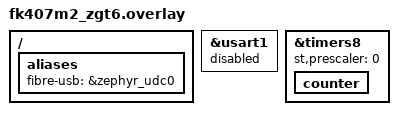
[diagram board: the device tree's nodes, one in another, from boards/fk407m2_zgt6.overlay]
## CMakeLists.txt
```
# SPDX-License-Identifier: Apache-2.0
#
# CASensorSim -- CA (crank angle) sensor signal simulator firmware.
#
# Zephyr app for the FK407M2-ZGT6 (STM32F407ZGT6) bench board. The
# bit-exact cas_core / cas_fault port of the casim golden model lives in
# cas/ (include/ + src/, plain library, host-testable with test/). The app
# layer (src/main.cpp) runs the 100 kHz TIM8 signal path and publishes the
# CasIntf telemetry/parameter interface over Fibre on the native USB bulk
# interface (Type-C connector); the interface autogen code is generated at
# build time from interface/cas_interface.yaml
# with the generator shipped in the Fibre module -- nothing generated is
# committed.
#
# The board is out-of-tree (boards/others/fk407m2_zgt6 in the platform
# workspace), so the workspace root is added to BOARD_ROOT.
#
# Build from the zephyrproject workspace (this repo is registered in
# manifest/west.yml as apps/cas-sim):
#
#   west build -p always -b fk407m2_zgt6 apps/cas-sim
#   west flash -d apps/cas-sim/build

cmake_minimum_required(VERSION 3.20.0)

# Version machinery (odrive_study model, see doc/guideline/version.md): the app
# line derives from this repo's git tags (+ version.txt target), the
# platform line from the workspace repo, checked against
# platform-requires.txt at configure time. The init calls must run before
# find_package(Zephyr) so the generated version.conf reaches kconfig.
include(${CMAKE_CURRENT_LIST_DIR}/../../scripts/git_version.cmake)
git_version_init(${CMAKE_CURRENT_LIST_DIR})
include(${CMAKE_CURRENT_LIST_DIR}/../../scripts/platform_version.cmake)
platform_version_init(${CMAKE_CURRENT_LIST_DIR})

# Platform lib module: provides the boot banner (util/banner), the Fibre
# transport backends (services/fibre-transport) and the rest of the platform
# services -- all of those default to n, so only what prj.conf enables
# (CONFIG_BANNER*, CONFIG_FIBRE_TRANSPORT*) compiles in.
list(APPEND EXTRA_ZEPHYR_MODULES
     ${CMAKE_CURRENT_LIST_DIR}/../../lib)

# Out-of-tree board root (boards/others/fk407m2_zgt6).
list(APPEND BOARD_ROOT ${CMAKE_CURRENT_LIST_DIR}/../..)

find_package(Zephyr REQUIRED HINTS $ENV{ZEPHYR_BASE})
project(cas_sensor_sim LANGUAGES C CXX)

# --------------------------------------------------------------------------
# Virtual CA engine (plain C, shared with the host golden test in test/).
add_subdirectory(cas)

# --------------------------------------------------------------------------
# Fibre interface codegen: interfaces.hpp / endpoints.cpp /
# static_exports.cpp are generated at build time from
# interface/cas_interface.yaml with the interface generator shipped in the
# Fibre module (single source of truth, same three-template invocation the
# upstream module uses).
set(FIBRE_DIR ${ZEPHYR_FIBRE_MODULE_DIR})
if(NOT FIBRE_DIR)
    # Fallback for setups where the module variable is not exported.
    set(FIBRE_DIR ${CMAKE_CURRENT_LIST_DIR}/../../modules/lib/fibre)
endif()
if(NOT EXISTS ${FIBRE_DIR}/tools/interface_generator.py)
    message(FATAL_ERROR "cas-sim: Fibre module not found at ${FIBRE_DIR} "
                        "(run 'west update')")
endif()
message(STATUS "cas-sim: using Fibre module at ${FIBRE_DIR}")

set(AUTOGEN_DIR ${CMAKE_CURRENT_BINARY_DIR}/autogen)
file(MAKE_DIRECTORY ${AUTOGEN_DIR})

# -W ignore::SyntaxWarning: the upstream generator emits harmless
# SyntaxWarnings for its own regex literals on every invocation.
add_custom_command(
  OUTPUT ${AUTOGEN_DIR}/interfaces.hpp
         ${AUTOGEN_DIR}/endpoints.cpp
         ${AUTOGEN_DIR}/static_exports.cpp
  COMMAND ${Python3_EXECUTABLE} -W ignore::SyntaxWarning
          ${FIBRE_DIR}/tools/interface_generator.py
          --definitions ${CMAKE_CURRENT_SOURCE_DIR}/interface/cas_interface.yaml
          --template ${FIBRE_DIR}/cpp/interfaces_template.j2
          --output ${AUTOGEN_DIR}/interfaces.hpp
  COMMAND ${Python3_EXECUTABLE} -W ignore::SyntaxWarning
          ${FIBRE_DIR}/tools/interface_generator.py
          --definitions ${CMAKE_CURRENT_SOURCE_DIR}/interface/cas_interface.yaml
          --template ${FIBRE_DIR}/cpp/legacy_endpoints_template.j2
          --output ${AUTOGEN_DIR}/endpoints.cpp
  COMMAND ${Python3_EXECUTABLE} -W ignore::SyntaxWarning
          ${FIBRE_DIR}/tools/interface_generator.py
          --definitions ${CMAKE_CURRENT_SOURCE_DIR}/interface/cas_interface.yaml
          --template ${FIBRE_DIR}/cpp/static_exports_template.j2
          --output ${AUTOGEN_DIR}/static_exports.cpp
  DEPENDS ${CMAKE_CURRENT_SOURCE_DIR}/interface/cas_interface.yaml
          ${FIBRE_DIR}/tools/interface_generator.py
          ${FIBRE_DIR}/cpp/interfaces_template.j2
          ${FIBRE_DIR}/cpp/legacy_endpoints_template.j2
          ${FIBRE_DIR}/cpp/static_exports_template.j2
  COMMENT "cas-sim: generating fibre autogen from interface YAML"
  VERBATIM
)

target_sources(app PRIVATE
    src/main.cpp
    src/logo.cpp
    ${AUTOGEN_DIR}/endpoints.cpp
    ${AUTOGEN_DIR}/static_exports.cpp
)

target_include_directories(app PRIVATE src ${AUTOGEN_DIR})

# Mirror the Fibre module's own build settings (see modules/lib/fibre/
# CMakeLists.txt): the Fibre headers expect <stdint.h> to be force-included
# and need RTTI (they use typeid/dynamic_cast but never exceptions).
# CONFIG_CPP_RTTI covers the -frtti part for app sources.
target_compile_options(app PRIVATE -include stdint.h)

# fibre-cpp uses ssize_t (channel_discoverer.cpp) without including
# <sys/types.h>; neither picolibc nor newlib provide it through the headers
# those sources include. zephyr_library_compile_options() passes the module's
# own "-include stdint.h" through a generated options_interface_lib_* helper
# target, so that is where the flag has to be redirected: point it at a
# header that also pulls in <sys/types.h> (src/fibre_libc_fix.h). This
# avoids both modifying the west-managed module checkout and appending a
# second "-include" pair, whose duplicate flag would be dropped by CMake's
# transitive option deduplication.
get_target_property(_fibre_libs ..__modules__lib__fibre LINK_LIBRARIES)
foreach(_fibre_lib ${_fibre_libs})
    if(_fibre_lib MATCHES "^options_interface_lib_")
        get_target_property(_fibre_opts ${_fibre_lib} INTERFACE_COMPILE_OPTIONS)
        list(FIND _fibre_opts "stdint.h" _fibre_stdint_idx)
        if(NOT _fibre_stdint_idx EQUAL -1)
            list(REMOVE_AT _fibre_opts ${_fibre_stdint_idx})
            list(INSERT _fibre_opts ${_fibre_stdint_idx}
                 "${CMAKE_CURRENT_LIST_DIR}/src/fibre_libc_fix.h")
            set_target_properties(${_fibre_lib}
                PROPERTIES INTERFACE_COMPILE_OPTIONS "${_fibre_opts}")
        endif()
    endif()
endforeach()
unset(_fibre_libs)
unset(_fibre_lib)
unset(_fibre_opts)
unset(_fibre_stdint_idx)

# Add APP_VERSION_* / PLATFORM_VERSION_* compile definitions once the app
# target exists, and generate the version description headers that firmware
# code includes ("app_version.h" / "platform_version.h").
git_version_finalize()
platform_version_finalize()
version_header_generate(${CMAKE_CURRENT_BINARY_DIR}/generated)
```

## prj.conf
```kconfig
# SPDX-License-Identifier: Apache-2.0
# CASensorSim -- CA sensor signal simulator firmware (FK407M2-ZGT6).
#
# The Fibre protocol (telemetry/parameter interface) runs over the native
# USB bulk interface on the Type-C connector (the board has no USB-UART
# bridge; the transport backend comes from the platform
# lib/services/fibre-transport service, see boards/fk407m2_zgt6.conf).
# USART1 is not used by this app (disabled in the app overlay). Console and
# shell stay disabled: the USB interface carries the protocol stream, and
# the boot banner is visible in the RTT debug build
# (`-DEXTRA_CONF_FILE=rtt.conf`, SEGGER RTT over SWD).

# The USB interface is Fibre's exclusive protocol stream: no console, no
# shell.
CONFIG_CONSOLE=n
CONFIG_SHELL=n
# Explicitly turn off UART_CONSOLE: the board defconfig enables it, but the
# assignment cannot take effect here (CONSOLE=n, no enabled UART instance),
# which makes Kconfig warn on every pristine build.
CONFIG_UART_CONSOLE=n

CONFIG_GPIO=y

# 10 us signal tick on TIM8 (Zephyr counter API); the ISR runs
# double-precision core math, so FP context sharing is required.
CONFIG_COUNTER=y
CONFIG_FPU=y
CONFIG_FPU_SHARING=y

# Fibre (C++ library, west module modules/lib/fibre).
CONFIG_CPP=y
CONFIG_STD_CPP11=y
CONFIG_REQUIRES_FULL_LIBCPP=y
# Fibre uses typeid/dynamic_cast (its module compiles with -frtti).
CONFIG_CPP_RTTI=y
CONFIG_FIBRE=y
# Note: the client role must stay enabled: with FIBRE_ENABLE_CLIENT=0 the
# fibre-cpp headers (legacy_protocol.hpp) do not compile because the Socket
# types they reference are only pulled in via the client headers.
CONFIG_FIBRE_ENABLE_SERVER=1
CONFIG_FIBRE_ENABLE_CLIENT=1
CONFIG_FIBRE_ZEPHYR_EVENT_LOOP=y

# Boot banner (platform module: lib/util/banner) with the CASIM logo. The
# default build has no console backend (the USB interface is Fibre's
# protocol stream), so the page is silently discarded there; it becomes
# visible in the RTT debug build (rtt.conf routes printk into the log
# backend).
CONFIG_BANNER=y
CONFIG_BANNER_LOGO=y
CONFIG_BANNER_PRODUCT="CASensorSim"
CONFIG_BANNER_NAME="CASIM"
```

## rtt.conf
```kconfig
# SPDX-License-Identifier: Apache-2.0
# Optional debug variant: SEGGER RTT logging over SWD (channel 0) while the
# USB bulk interface stays exclusive to the Fibre protocol.
#
#   west build -p always -b fk407m2_zgt6 apps/cas-sim -d apps/cas-sim/build-rtt \
#       -- -DEXTRA_CONF_FILE=rtt.conf
#
# Then expose the RTT channel with OpenOCD:
#   openocd -f interface/stlink.cfg -f target/stm32f4x.cfg \
#       -c "adapter speed 100" -c init -c "reset run" \
#       -c 'rtt setup <addr of _SEGGER_RTT> 0x100 "SEGGER RTT"' \
#       -c "rtt start" -c "rtt server start 9090 0"
#
#   nc 127.0.0.1 9090        # logs (cas-sim + fibre protocol)

CONFIG_LOG=y
CONFIG_USE_SEGGER_RTT=y
CONFIG_LOG_BACKEND_RTT=y
# Route printk (the boot banner page) into the log backend so it reaches
# RTT as well.
CONFIG_LOG_PRINTK=y
```

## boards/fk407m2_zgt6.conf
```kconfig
# SPDX-License-Identifier: Apache-2.0
# CASensorSim on FK407M2-ZGT6: native USB bulk transport for the Fibre
# protocol (Type-C connector; the board has no USB-UART bridge).
#
# The Fibre transport backend lives in the platform lib module
# (lib/services/fibre-transport service), which requires the USB device
# stack. These
# settings mirror the platform board fragment used by the matrix-cards app
# -- cas-sim does not inherit that fragment because it defines its own
# app-level board overlay.

CONFIG_USB_DEVICE_STACK_NEXT=y
CONFIG_FIBRE_TRANSPORT=y
CONFIG_FIBRE_TRANSPORT_USB=y

# USB identity on the host.
CONFIG_FIBRE_TRANSPORT_USB_MANUFACTURER="Xiaofeng"
CONFIG_FIBRE_TRANSPORT_USB_PRODUCT="CASensorSim"

# USB stack stability under the 10 us TIM8 signal-tick load.
CONFIG_UDC_STM32_STACK_SIZE=1024
CONFIG_USBD_THREAD_STACK_SIZE=2048
```

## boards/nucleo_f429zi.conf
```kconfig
# SPDX-License-Identifier: Apache-2.0
# CASensorSim on NUCLEO-F429ZI: Fibre runs over USART3 (the `fibre-uart`
# alias in boards/nucleo_f429zi.overlay) through the platform fibre-transport
# service (mounted in the platform lib module).

CONFIG_FIBRE_TRANSPORT=y
CONFIG_FIBRE_TRANSPORT_UART=y
```

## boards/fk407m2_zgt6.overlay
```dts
/*
 * SPDX-License-Identifier: Apache-2.0
 *
 * CASensorSim app overlay for the FK407M2-ZGT6 (STM32F407ZGT6).
 *
 * The Fibre protocol (CasIntf telemetry/parameter interface) runs over a
 * vendor-specific USB bulk interface on the Type-C connector: the board has
 * no USB-UART bridge, so the native USB device controller is used directly
 * (host side: libusb; the interface carries the Fibre protocol as a raw
 * byte stream). The `fibre-usb` alias below selects the UDC controller for
 * the platform fibre-transport service, which builds the USBD context and
 * the vendor interface (class codes 0xFF/0x01/0x01) on top of it.
 *
 * USART1 is not used by this app and is disabled below, so PA9/PA10 stay
 * free. Console and shell are disabled in prj.conf: the USB interface
 * carries the protocol stream, and the boot banner is visible in the RTT
 * debug build (rtt.conf).
 *
 * Signal generation timing: TIM8 update events at 100 kHz (10 us tick,
 * pin-partition plan); the update interrupt drives cas_step(), the fault
 * injection, the PE0..PE7 output stage and the telemetry mirror (see
 * src/main.cpp).
 */

/ {
	aliases {
		fibre-usb = &zephyr_udc0;
	};
};

&usart1 {
	status = "disabled";
};

&timers8 {
	status = "okay";
	st,prescaler = <0>;

	counter {
		status = "okay";
	};
};
```

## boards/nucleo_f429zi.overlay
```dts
/*
 * SPDX-License-Identifier: Apache-2.0
 *
 * CASensorSim app overlay for the NUCLEO-F429ZI (kept buildable next to
 * the FK407M2-ZGT6 target). USART3 (ST-LINK VCP) carries the Fibre
 * protocol (`fibre-uart` alias); console and shell are disabled in
 * prj.conf. Same signal timing as the fk407m2_zgt6 target: TIM8 update
 * events at 100 kHz driving cas_step() (see src/main.cpp).
 */

/ {
	aliases {
		fibre-uart = &usart3;
	};
};

&timers8 {
	status = "okay";
	st,prescaler = <0>;

	counter {
		status = "okay";
	};
};
```

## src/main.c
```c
/*
 * CASensorSim -- CA (crank angle) sensor signal simulator firmware.
 *
 * Bring-up skeleton for the NUCLEO-F429ZI test-bench board: LED heartbeat
 * to prove the target is alive. The actual product generates 8 digital
 * pickoff channels (TDC1/REF1/A/B/REF2/C/D/TDC2) + 2 SSI absolute-angle
 * streams in real time from a virtual flywheel; the bit-exact core port
 * (cas_core.c / cas_fault.c per HANDOFF.md #7) is the active task and
 * will be driven from a timer here.
 */

#include <errno.h>

#include <zephyr/kernel.h>
#include <zephyr/drivers/gpio.h>

#define BLINK_INTERVAL_MS 500

static const struct gpio_dt_spec led = GPIO_DT_SPEC_GET(DT_ALIAS(led0), gpios);

int main(void)
{
	if (!gpio_is_ready_dt(&led)) {
		printk("CASensorSim: LED device not ready\n");
		return -ENODEV;
	}
	if (gpio_pin_configure_dt(&led, GPIO_OUTPUT_ACTIVE) < 0) {
		printk("CASensorSim: LED configure failed\n");
		return -EIO;
	}

	printk("CASensorSim firmware skeleton (%s)\n", CONFIG_BOARD_TARGET);
	printk("cas_core port pending -- see HANDOFF.md #7\n");

	while (1) {
		gpio_pin_toggle_dt(&led);
		k_msleep(BLINK_INTERVAL_MS);
	}
	return 0;
}
```

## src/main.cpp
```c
/*
 * SPDX-License-Identifier: Apache-2.0
 *
 * CASensorSim -- CA (crank angle) sensor signal simulator firmware.
 *
 * App layer for the FK407M2-ZGT6 (STM32F407ZGT6) bench board. Two
 * concurrent activities:
 *
 *   1. Signal path (100 kHz TIM8 update ISR, 10 us tick per the
 *      pin-partition plan): cas_step() -> cas_fault_apply() -> GPIO
 *      output stage CH00..CH07 = PE0..PE7 (dig[] levels with a single
 *      BSRR write; oe=0 switches the pin to input = high-Z, FR-30) and
 *      the telemetry mirror refresh (below).
 *   2. Fibre protocol over the native USB bulk interface (`fibre-usb`
 *      alias): exposes the CasIntf interface
 *      (interface/cas_interface.yaml) -- readonly telemetry attributes +
 *      set_rpm / set_dig_fault / set_ssi_fault / clear_faults. The Fibre
 *      stack runs in its own event-loop thread; protocol calls never run
 *      in ISR context. The transport backend (fibre_transport::UsbBackend)
 *      comes from the platform lib/services/fibre-transport service.
 *
 * Concurrency model:
 *   - The ISR writes the CasObject telemetry members every tick (plain
 *     32-bit aligned stores; sample_count is 64 bit and may tear when
 *     read -- acceptable for a monotonic counter). The Fibre property
 *     layer reads the members through a pointer at request time, so
 *     host reads always see the latest tick's values.
 *   - Parameter writes (set_rpm / set_*_fault / clear_faults) run on the
 *     event-loop thread and are guarded with irq_lock() so the ISR can
 *     never observe a half-updated profile or fault set.
 *
 * SSI: both absolute-angle words are computed every tick; their pin
 * layer (PA8/PC0 + RS-485 DIR, TIM6 protocol timing) is a later step.
 *
 * Console and shell are disabled (the Fibre transport owns the protocol
 * interface); build with `-DEXTRA_CONF_FILE=rtt.conf` for logs over SEGGER
 * RTT (SWD). The host-side counterpart is host/cas_fibre_test.py.
 */

#include <cmath>

#include <zephyr/kernel.h>
#include <zephyr/drivers/counter.h>
#include <zephyr/drivers/gpio.h>
#include <zephyr/irq.h>
#include <zephyr/logging/log.h>

#include <fibre/fibre.hpp>
#include <fibre/zephyr_event_loop.hpp>

#include "app_version.h"
#include "banner.h"

#include <usb_backend.hpp>
#include "interfaces.hpp"

#include "cas_core.h"
#include "cas_fault.h"
#include "cas_preset.h"

LOG_MODULE_REGISTER(cas_sim);

namespace {

/* --------------------------------------------------------------------------
 * Signal path constants
 */

/* Signal tick: 10 us update events (pin-partition plan, TIM8). */
constexpr uint32_t CAS_TICK_HZ = 100000u;

/* CH00..CH07 sit on PE0..PE7. */
constexpr uint32_t CAS_DIG_MASK = 0xFFu;

/* Firmware version reported over Fibre, encoded (major<<16)|(minor<<8)|patch.
 * Derived at build time from this repo's git state (the generated
 * app_version.h; see CMakeLists.txt) instead of a hardcoded constant: it
 * follows the vX.Y.Z tag / version.txt target of the CASensorSim repo. */
constexpr uint32_t CASIM_FW_VERSION =
    (static_cast<uint32_t>(APP_VERSION_MAJOR) << 16) |
    (static_cast<uint32_t>(APP_VERSION_MINOR) << 8) |
    static_cast<uint32_t>(APP_VERSION_PATCH);

/* --------------------------------------------------------------------------
 * Engine + output stage state (ISR context)
 */

cas_state_t cas_st;
cas_fault_t cas_faults;

/* oe[] bits currently driven as outputs (mode change only on toggle). */
gpio_port_pins_t oe_driven;

const struct gpio_dt_spec led = GPIO_DT_SPEC_GET(DT_ALIAS(led0), gpios);
const struct device *const dig_port = DEVICE_DT_GET(DT_NODELABEL(gpioe));
const struct device *const tick_cnt =
	DEVICE_DT_GET(DT_CHILD(DT_NODELABEL(timers8), counter));

/* --------------------------------------------------------------------------
 * Published Fibre object
 *
 * Member naming is dictated by the generated CasIntfWrapper: every YAML
 * attribute maps to a member `<name>_` (read live through a pointer when
 * the host reads the property), every function to a method.
 */
class CasObject {
public:
    /* -- telemetry (written by the signal ISR every tick) -- */
    uint32_t firmware_version_ = CASIM_FW_VERSION;
    uint32_t tick_hz_ = CAS_TICK_HZ;
    float rpm_ = 0.0f;
    float theta_deg_ = 0.0f;
    uint8_t dig_mask_ = 0;
    uint8_t oe_mask_ = 0;
    int32_t ssi1_ = 0;
    int32_t ssi2_ = 0;
    uint64_t sample_count_ = 0;

    /* -- parameters (event-loop thread, irq_lock() against the ISR) --
     *
     * The legacy Fibre protocol only carries fixed-size int/uint function
     * payloads: enable/pfb/hold/fail flags are uint8 (0/1), the return
     * value is uint8 (1 = accepted, 0 = rejected) and set_rpm takes the
     * speed in milli-rpm (60000 = 60.000 rpm, negative = reverse). */

    uint8_t set_rpm(int32_t rpm_mrpm) {
        double rpm = (double)rpm_mrpm / 1000.0;

        if (!std::isfinite(rpm)) {
            return 0;
        }
        unsigned key = irq_lock();

        cas_st.prof.type = CAS_PROF_CONST;
        cas_st.prof.rpm = rpm;
        irq_unlock(key);
        return 1;
    }

    uint8_t set_dig_fault(uint8_t channel, uint8_t enable, uint8_t trigger,
                          uint32_t angle_mdeg, uint32_t every_n) {
        if (channel >= CAS_N_DIG || trigger > CAS_FT_EVERY_N_SSI) {
            return 0;
        }
        unsigned key = irq_lock();
        cas_fault_cond_t *cond = &cas_faults.dig[channel].cond;

        cond->enable = (enable != 0u);
        cond->trigger = (cas_fault_trigger_t)trigger;
        cond->angle_mdeg = angle_mdeg;
        cond->every_n = every_n;
        cond->active = false; /* re-arm the latch */
        irq_unlock(key);
        return 1;
    }

    uint8_t set_ssi_fault(uint8_t channel, uint8_t enable, uint8_t trigger,
                          uint32_t angle_mdeg, uint32_t every_n, uint8_t pfb,
                          int32_t offset_mdeg, uint8_t hold,
                          int32_t single_frame_delta, uint8_t fail) {
        if (channel >= CAS_N_SSI || trigger > CAS_FT_EVERY_N_SSI) {
            return 0;
        }
        unsigned key = irq_lock();
        cas_ssi_fault_t *f = &cas_faults.ssi[channel];
        cas_fault_cond_t *cond = &f->cond;

        cond->enable = (enable != 0u);
        cond->trigger = (cas_fault_trigger_t)trigger;
        cond->angle_mdeg = angle_mdeg;
        cond->every_n = every_n;
        cond->active = false; /* re-arm the latch */
        f->pfb = (pfb != 0u);
        f->offset_mdeg = offset_mdeg;
        f->hold = (hold != 0u);
        f->single_frame_delta = single_frame_delta;
        f->fail = (fail != 0u);
        irq_unlock(key);
        return 1;
    }

    void clear_faults() {
        unsigned key = irq_lock();

        cas_fault_reset(&cas_faults); /* FR-34 all-off state */
        irq_unlock(key);
    }
};

CasObject cas_object_;
CasIntfWrapper<CasObject> cas_object_wrapper_{cas_object_};

/* Stable node ID so the host recognizes the device across reboots. */
const uint8_t kNodeId[16] = {
    'C', 'A', 'S', 'S', 'I', 'M', 'F', 'W',
    0x00, 0x00, 0x00, 0x00, 0x00, 0x00, 0x00, 0x01,
};

/* Consistency between the devicetree alias and the enabled fibre-transport
 * backend. */
#if DT_NODE_EXISTS(DT_ALIAS(fibre_usb)) && !defined(CONFIG_FIBRE_TRANSPORT_USB)
#error "fibre-usb devicetree alias present but CONFIG_FIBRE_TRANSPORT_USB is not enabled"
#endif

fibre_transport::UsbBackend transport_backend_;
fibre::ZephyrEventLoop event_loop_;

/* --------------------------------------------------------------------------
 * Signal path (ISR context)
 */

/* Telemetry mirror: copy the tick's engine state into the published
 * Fibre object. Plain stores; see the concurrency note in the header
 * comment. */
void telemetry_refresh(void)
{
	uint8_t dig = 0;
	uint8_t oe = 0;

	for (int ch = 0; ch < CAS_N_DIG; ch++) {
		if (cas_st.dig[ch] != 0u) {
			dig |= BIT(ch);
		}
		if (cas_st.oe[ch] != 0u) {
			oe |= BIT(ch);
		}
	}
	cas_object_.rpm_ = (float)cas_st.rpm;
	cas_object_.theta_deg_ = (float)cas_st.theta;
	cas_object_.dig_mask_ = dig;
	cas_object_.oe_mask_ = oe;
	cas_object_.ssi1_ = cas_st.ssi1;
	cas_object_.ssi2_ = cas_st.ssi2;
	cas_object_.sample_count_++;
}

void tick_isr(const struct device *dev, void *user_data)
{
	gpio_port_pins_t oe = 0;
	uint32_t level = 0;

	ARG_UNUSED(dev);
	ARG_UNUSED(user_data);

	/* One engine sample + fault application per tick. */
	cas_step(&cas_st);
	cas_fault_apply(&cas_faults, &cas_st);

	for (int ch = 0; ch < CAS_N_DIG; ch++) {
		if (cas_st.oe[ch] != 0u) {
			oe |= BIT(ch);
		}
		if (cas_st.dig[ch] != 0u) {
			level |= BIT(ch);
		}
	}

	if (oe != oe_driven) {
		/* oe changed: driven output vs high-Z input (FR-30). */
		gpio_port_pins_t changed = oe ^ oe_driven;

		for (int ch = 0; ch < CAS_N_DIG; ch++) {
			if ((changed & BIT(ch)) == 0u) {
				continue;
			}
			(void)gpio_pin_configure(dig_port, ch,
						 (oe & BIT(ch)) != 0u
							 ? GPIO_OUTPUT
							 : GPIO_INPUT);
		}
		oe_driven = oe;
	}

	/* One BSRR write for all 8 levels; input-mode pins ignore it. */
	gpio_port_set_masked_raw(dig_port, CAS_DIG_MASK, level);

	telemetry_refresh();
}

/* Wire the signal path: PE0..7 as high-Z inputs, then the 10 us tick. */
int signal_path_start(void)
{
	if (!device_is_ready(dig_port)) {
		LOG_ERR("GPIOE not ready");
		return -ENODEV;
	}
	if (!device_is_ready(tick_cnt)) {
		LOG_ERR("TIM8 counter not ready");
		return -ENODEV;
	}

	oe_driven = 0;
	for (int ch = 0; ch < CAS_N_DIG; ch++) {
		int rc = gpio_pin_configure(dig_port, ch, GPIO_INPUT);

		if (rc != 0) {
			LOG_ERR("PE%d configure failed: %d", ch, rc);
			return rc;
		}
	}

	uint32_t freq = counter_get_frequency(tick_cnt);
	uint32_t ticks = freq / CAS_TICK_HZ;

	if (freq < CAS_TICK_HZ || (freq % CAS_TICK_HZ) != 0u ||
	    ticks == 0u || ticks > 0x10000u) {
		LOG_ERR("TIM8 clock %u Hz cannot tick at %u Hz", freq,
			CAS_TICK_HZ);
		return -EINVAL;
	}

	struct counter_top_cfg top = {};

	top.ticks = ticks - 1u; /* ARR: period = ticks + 1 clocks */
	top.callback = tick_isr;

	int rc = counter_set_top_value(tick_cnt, &top);

	if (rc != 0) {
		LOG_ERR("TIM8 top value failed: %d", rc);
		return rc;
	}
	rc = counter_start(tick_cnt);
	if (rc != 0) {
		LOG_ERR("TIM8 start failed: %d", rc);
	}
	return rc;
}

/* --------------------------------------------------------------------------
 * Fibre -> Zephyr log bridge
 *
 * Only produces output in builds with a log backend (rtt.conf); compiled out
 * otherwise.
 */

void fibre_log_bridge(void * /*ctx*/, const char *file, unsigned line,
		      int level, uintptr_t /*info0*/, uintptr_t /*info1*/,
		      const char *text)
{
	if (level >= 4) { /* kDebug / kTrace */
		LOG_DBG("fibre: %s:%u: %s", file, line, text ? text : "");
	} else if (level == 1) { /* kError */
		LOG_ERR("fibre: %s:%u: %s", file, line, text ? text : "");
	} else {
		LOG_INF("fibre: %s:%u: %s", file, line, text ? text : "");
	}
}

fibre::Logger fibre_logger_{fibre::log_fn_t{&fibre_log_bridge, nullptr},
			    fibre::LogLevel::kDebug};

/* --------------------------------------------------------------------------
 * Event loop startup
 *
 * Everything that touches the Fibre stack must run on the event loop thread,
 * so the whole setup happens in the on_started callback. The functor lives at
 * namespace scope because Callback stores a pointer to it.
 */

struct OnStarted {
	void operator()() const
	{
		fibre::Fibre *ctx = nullptr;

		if (fibre::open(&event_loop_, fibre_logger_, &ctx).is_error()) {
			LOG_ERR("failed to open Fibre context");
			return;
		}

		if (ctx->init_backend("usb", &transport_backend_).is_error()) {
			LOG_ERR("failed to initialize USB backend");
			return;
		}

		/* Domain path "<transport>:<specs>": the USB backend ignores
		 * the specs part (single fixed interface). */
		fibre::Domain *domain = ctx->create_domain("usb:", kNodeId, {});
		if (!domain) {
			LOG_ERR("failed to create Fibre domain");
			return;
		}

		LOG_INF("fibre: domain ready, serving cas_object over USB bulk");
	}
};

const OnStarted on_started_{};

} // namespace

/* Consumed by the generated static_exports.cpp ("must be defined by the
 * application"). The generated interface classes live in the global
 * namespace. */
CasIntfIntf *cas_object_ptr = &cas_object_wrapper_;

int main(void)
{
	banner_print();

	if (!gpio_is_ready_dt(&led)) {
		LOG_ERR("LED device not ready");
		return -ENODEV;
	}
	if (gpio_pin_configure_dt(&led, GPIO_OUTPUT_INACTIVE) < 0) {
		LOG_ERR("LED configure failed");
		return -EIO;
	}

	/* Power-up state: engine stopped (const 0 rpm), all faults off
	 * (FR-34). The speed and fault set come in over Fibre. */
	cas_cfg_t cfg;
	cas_profile_t prof = {};
	cas_ssi_cfg_t ssi = {};

	prof.type = CAS_PROF_CONST;
	prof.rpm = 0.0;

	cas_preset_x1plus(&cfg);
	cas_fault_reset(&cas_faults);
	cas_init(&cas_st, &cfg, &prof, &ssi, 1.0 / (double)CAS_TICK_HZ);

	LOG_INF("CASensorSim: X1+ preset (186 teeth), const 0 rpm, "
		"tick %u Hz, CH00..07 = PE0..7",
		CAS_TICK_HZ);

	int rc = signal_path_start();

	if (rc != 0) {
		LOG_ERR("signal path start failed: %d", rc);
		return rc;
	}

	if (event_loop_.start(fibre_logger_, fibre::Callback<void>{on_started_})
		    .is_error()) {
		LOG_ERR("failed to start Fibre event loop");
		return 1;
	}

	/* Heartbeat: blink the on-board LED (PC13, active low). */
	for (;;) {
		gpio_pin_toggle_dt(&led);
		k_msleep(500);
	}
	return 0;
}
```

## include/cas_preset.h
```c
/*
 * Preset sensor/flywheel configurations, all angles in milli-degree
 * (1 deg = 1000 mDeg, 1 rev = 360000 mDeg) -- the same unit and field
 * names as the X1+ CA Generator GUI and the web dashboard PRESETS
 * (doc/ca sensor sim/configs/x1plus.json).
 *
 * These are parameters, not constants: the firmware fills a cas_cfg_t
 * from whichever preset (or a user-provided one) and passes it to
 * cas_init(); re-initializing with a different cfg switches the
 * simulated engine. Channel order = NI 9474 wiring:
 * CH00 TDC1, CH01 REF1, CH02 A, CH03 B, CH04 REF2, CH05 C, CH06 D, CH07 TDC2.
 */
#ifndef CAS_PRESET_H
#define CAS_PRESET_H

#include "cas_core.h"

/*
 * X1+ test-rig CA Generator GUI preset (gui_config.py gui_to_spec on
 * configs/x1plus.json): REF1/REF2 pulse center 180.0 deg (width 1.0),
 * TDC1/TDC2 center 0.2 deg (width 1.0), tooth width 0.6 deg,
 * B/D offset +300 mDeg against A/C. This is the bit-exact golden
 * baseline configuration (HANDOFF.md 6).
 */
static inline void cas_preset_x1plus(cas_cfg_t *cfg)
{
	*cfg = (cas_cfg_t){
		.teeth = 186,
		.tooth0_mdeg = 0,
		.ref1_mark_mdeg = 0,
		.ref2_mark_mdeg = 0,
		.tdc_mark_mdeg = 0,
		.pos_mdeg = {200,    /* CH00 TDC1  (center 0.2 deg)  */
			     180000, /* CH01 REF1  (center 180 deg)  */
			     180000, /* CH02 A     (offset 0 vs REF1)*/
			     180300, /* CH03 B     (offset +300)     */
			     180000, /* CH04 REF2  (center 180 deg)  */
			     180000, /* CH05 C     (offset 0 vs REF2)*/
			     180300, /* CH06 D     (offset +300)     */
			     200},   /* CH07 TDC2  (center 0.2 deg)  */
		.width_mdeg = {1000, 1000, 600, 600, 1000, 600, 600, 1000},
	};
}

/*
 * casim SensorSpec defaults: 100-tooth flywheel, A/B and C/D mounted
 * 0.9 / 2.7 deg, REF sensors at 0 deg, all marks at 0 deg.
 */
static inline void cas_preset_default100(cas_cfg_t *cfg)
{
	*cfg = (cas_cfg_t){
		.teeth = 100,
		.pos_mdeg = {0,    /* CH00 TDC1 */
			     0,    /* CH01 REF1 */
			     900,  /* CH02 A    */
			     2700, /* CH03 B    */
			     0,    /* CH04 REF2 */
			     900,  /* CH05 C    */
			     2700, /* CH06 D    */
			     0},   /* CH07 TDC2 */
		.width_mdeg = {500, 600, 1800, 1800, 600, 1800, 1800, 500},
	};
}

#endif /* CAS_PRESET_H */
```

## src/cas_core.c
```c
/*
 * cas_core implementation -- see cas_core.h for the bit-exactness rules.
 *
 * Every formula below mirrors one casim source line (file/line references
 * in comments). Operation order is normative: changing it changes the
 * low bits and breaks the golden-hash verification (HANDOFF.md 6).
 */

#include <math.h>

#include "cas_core.h"

#ifndef M_PI
#define M_PI 3.14159265358979323846
#endif

/* Channel index map (NI 9474 wiring): CH00 TDC1, CH01 REF1, CH02 A,
 * CH03 B, CH04 REF2, CH05 C, CH06 D, CH07 TDC2.
 * Tooth-pickup channels share the flywheel gear; the rest read marks. */
#define CH_TDC1 0
#define CH_REF1 1
#define CH_A    2
#define CH_B    3
#define CH_REF2 4
#define CH_C    5
#define CH_D    6
#define CH_TDC2 7

static bool ch_is_tooth(int ch)
{
	return ch == CH_A || ch == CH_B || ch == CH_C || ch == CH_D;
}

double cas_fmod_pos(double x, double m)
{
	/* Python float % m: result in [0, m) with the divisor's sign. */
	double r = fmod(x, m);
	if (r < 0.0) {
		r += m;
	}
	return r;
}

double cas_rne(double x)
{
	/* np.round: round-half-to-even (banker's rounding). */
	double f = floor(x);
	double d = x - f;
	if (d > 0.5) {
		return f + 1.0;
	}
	if (d < 0.5) {
		return f;
	}
	/* d == 0.5: tie -> even mantissa */
	if (fmod(f, 2.0) == 0.0) {
		return f;
	}
	return f + 1.0;
}

double cas_profile_rpm(const cas_profile_t *prof, double t)
{
	switch (prof->type) {
	case CAS_PROF_CONST:
		/* profile.py ConstantSpeed.speed() */
		return prof->rpm;

	case CAS_PROF_RAMP: {
		/* profile.py RampSpeed.speed(), cycle=False:
		 *   clip(start + accel*t, min(start, target), max(start, target)) */
		double lo = fmin(prof->start_rpm, prof->target_rpm);
		double hi = fmax(prof->start_rpm, prof->target_rpm);
		double v = prof->accel_rpm * t;

		/* Multiply and add live in separate statements on purpose:
		 * no FMA contraction may reorder the rounding. */
		return fmin(fmax(prof->start_rpm + v, lo), hi);
	}

	case CAS_PROF_RAMP_CYCLE: {
		/* profile.py RampSpeed.speed(), cycle=True */
		double a = fabs(prof->accel_rpm);
		if (a == 0.0) {
			a = 1e-9; /* abs(accel) or 1e-9 */
		}
		double d_up = (prof->target_rpm - prof->start_rpm) / a;
		double d_down = (prof->target_rpm - prof->ret_rpm) / a;
		double period = d_up + d_down;
		double tc = cas_fmod_pos(t, period);
		double rise = prof->accel_rpm * fmin(tc, d_up);
		double fall = prof->accel_rpm *
			      fmin(fmax(tc - d_up, 0.0), d_down);
		double up = prof->start_rpm + rise;
		double down = prof->target_rpm - fall;

		return (tc <= d_up) ? up : down;
	}

	case CAS_PROF_FLUCT: {
		/* profile.py Fluctuation.speed(): base + amp*sin(2*pi*f*t).
		 * Note: sin() is libm-dependent -- cross-platform results may
		 * differ in the last ulp (VR-01 tolerates +-1 sample). */
		double wave = prof->amp_rpm *
			      sin(2.0 * M_PI * prof->freq_hz * t);

		return prof->rpm + wave;
	}

	default:
		return prof->rpm;
	}
}

/* Compute dig[]/oe[]/ssi1/ssi2 for the current theta (sensor.py signals(),
 * square_wave() and ssi.py words()). */
static void cas_compute(cas_state_t *st)
{
	for (int ch = 0; ch < CAS_N_DIG; ch++) {
		/* square_wave(): rel = (angle - center + 0.5*width) % period
		 * (multiply and add split across statements: no FMA). */
		double half = 0.5 * st->width[ch];
		double rel = cas_fmod_pos((st->theta - st->center[ch]) + half,
					  st->period[ch]);

		st->dig[ch] = (rel < st->width[ch]) ? 1u : 0u;
		st->oe[ch] = 1u; /* healthy default; fault module clears */
	}

	for (int s = 0; s < CAS_N_SSI; s++) {
		/* ssi.py _counts(): a = (angle + offset) % 360;
		 * counts = round(a/360*resolution) % resolution */
		double a = cas_fmod_pos(st->theta + st->ssi_off[s],
					CAS_REV_DEG);
		double c = cas_rne((a / CAS_REV_DEG) *
				   (double)CAS_SSI_RESOLUTION);
		int32_t word = (int32_t)fmod(c, (double)CAS_SSI_RESOLUTION);
		if (st->pfb[s]) {
			word |= 1 << CAS_SSI_PFB_SHIFT;
		}
		if (s == 0) {
			st->ssi1 = word;
		} else {
			st->ssi2 = word;
		}
	}
}

void cas_init(cas_state_t *st, const cas_cfg_t *cfg,
	      const cas_profile_t *prof, const cas_ssi_cfg_t *ssi, double dt)
{
	double tooth_period = CAS_REV_DEG / (double)cfg->teeth;

	st->dt = dt;
	st->start = 0.0; /* start angle fixed at 0 deg for now */
	st->cum = 0.0;
	st->prof = *prof;

	/* Precompute per-channel geometry: center = (pos - mark) mod period
	 * (sensor.py centers()); tooth channels use period P and tooth0 as
	 * the mark, mark channels use 360 deg and their own mark. */
	for (int ch = 0; ch < CAS_N_DIG; ch++) {
		double pos = (double)cfg->pos_mdeg[ch] / 1000.0;
		double mark;

		if (ch_is_tooth(ch)) {
			mark = (double)cfg->tooth0_mdeg / 1000.0;
			st->period[ch] = tooth_period;
		} else if (ch == CH_REF1) {
			mark = (double)cfg->ref1_mark_mdeg / 1000.0;
			st->period[ch] = CAS_REV_DEG;
		} else if (ch == CH_REF2) {
			mark = (double)cfg->ref2_mark_mdeg / 1000.0;
			st->period[ch] = CAS_REV_DEG;
		} else { /* TDC1 / TDC2 share the unique TDC mark */
			mark = (double)cfg->tdc_mark_mdeg / 1000.0;
			st->period[ch] = CAS_REV_DEG;
		}

		st->center[ch] = cas_fmod_pos(pos - mark, st->period[ch]);
		st->width[ch] = (double)cfg->width_mdeg[ch] / 1000.0;
	}

	st->ssi_off[0] = (double)ssi->ssi1_off_mdeg / 1000.0;
	st->ssi_off[1] = (double)ssi->ssi2_off_mdeg / 1000.0;
	st->pfb[0] = ssi->pfb1;
	st->pfb[1] = ssi->pfb2;

	/* Sample k=0: t = 0*dt, theta = start + 0 (generator.py run()). */
	st->k = 0;
	st->t = (double)st->k * st->dt;
	st->rpm = cas_profile_rpm(&st->prof, st->t);
	st->rpm_prev = st->rpm;
	st->theta = st->start + st->cum;
	cas_compute(st);
}

void cas_step(cas_state_t *st)
{
	/* generator.py run(): inc = 0.5*(rpm[1:] + rpm[:-1])*6.0*dt;
	 * angle = start + cumsum(inc). Order per HANDOFF.md 7.3-2; the
	 * product is materialized in `inc` first so no FMA contraction
	 * can fuse it into the accumulation. */
	double inc;
	double rpm_new;

	st->k = st->k + 1;
	st->t = (double)st->k * st->dt;
	rpm_new = cas_profile_rpm(&st->prof, st->t);
	inc = ((0.5 * (st->rpm_prev + rpm_new)) * 6.0) * st->dt;
	st->cum += inc;
	st->theta = st->start + st->cum;
	st->rpm_prev = rpm_new;
	st->rpm = rpm_new;

	cas_compute(st);
}
```

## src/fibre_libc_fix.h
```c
/*
 * SPDX-License-Identifier: Apache-2.0
 *
 * Replacement for the "-include stdint.h" that the Fibre module applies to
 * its own sources (see modules/lib/fibre/CMakeLists.txt). Shared with
 * tests/fibre-test (same file).
 *
 * fibre-cpp uses POSIX types (ssize_t in channel_discoverer.cpp) without
 * including <sys/types.h>; neither picolibc nor newlib provide it through
 * the headers those sources include. This header force-includes both, so a
 * single "-include" flag covers the module's original stdint.h requirement
 * and the missing POSIX types at once.
 *
 * The indirection exists because a second "-include <file>" pair appended to
 * the module target gets broken up by CMake's compile option
 * deduplication, which would leave the module's own stdint.h argument bare
 * (parsed as an input file).
 */

#include <stdint.h>
#include <sys/types.h>
```

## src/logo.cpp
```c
/*
 * SPDX-License-Identifier: Apache-2.0
 *
 * CASensorSim boot logo: the application-side override of the banner
 * library's weak banner_logo() hook (enabled with CONFIG_BANNER_LOGO).
 * The block letters spell the product name; the Unicode art needs a
 * UTF-8 terminal.
 */

#include <zephyr/kernel.h>

#include "banner.h"

#define LOGO_CYAN  "\033[1;36m"
#define LOGO_RESET "\033[0m"

extern "C" void banner_logo(void)
{
	printk(LOGO_CYAN
	       "   ███████╗  █████╗  ███████╗ ██╗ ███╗   ███╗\n"
	       "   ██╔════╝ ██╔══██╗ ██╔════╝ ██║ ████╗ ████║\n"
	       "   ██║      ███████║ ███████╗ ██║ ██╔████╔██║\n"
	       "   ██║      ██╔══██║ ╚════██║ ██║ ██║╚██╔╝██║\n"
	       "   ╚██████╗ ██║  ██║ ███████║ ██║ ██║ ╚═╝ ██║\n"
	       "   ╚═════╝  ╚═╝  ╚═╝ ╚══════╝ ╚═╝ ╚═╝     ╚═╝\n"
	       LOGO_RESET);
}
```

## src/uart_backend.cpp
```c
/*
 * SPDX-License-Identifier: Apache-2.0
 *
 * Fibre transport backend over a Zephyr UART, see uart_backend.hpp.
 * Shared with tests/fibre-test (same file, renamed namespace).
 */

#include "uart_backend.hpp"

#include <fibre/fibre.hpp>

#include <zephyr/irq.h>

using namespace fibre; // NOLINT -- the Fibre API is used pervasively below

namespace cas_sim {

RichStatus UartBackend::init(EventLoop* event_loop, Logger logger) {
    F_RET_IF(event_loop_, "already initialized");
    F_RET_IF(!event_loop, "invalid argument");

    dev_ = DEVICE_DT_GET(DT_ALIAS(fibre_uart));
    F_RET_IF(!device_is_ready(dev_), "UART device not ready");

    event_loop_ = event_loop;
    logger_ = logger;

    uart_irq_callback_user_data_set(dev_, uart_isr_, this);
    uart_irq_rx_enable(dev_);

    return RichStatus::success();
}

RichStatus UartBackend::deinit() {
    F_RET_IF(!event_loop_, "not initialized");
    if (dev_) {
        uart_irq_rx_disable(dev_);
        uart_irq_tx_disable(dev_);
        uart_irq_callback_user_data_set(dev_, nullptr, nullptr);
    }
    event_loop_ = nullptr;
    logger_ = Logger::none();
    return RichStatus::success();
}

void UartBackend::start_channel_discovery(Domain* domain, const char* specs,
                                          size_t specs_len,
                                          ChannelDiscoveryContext** handle) {
    (void)specs;
    (void)specs_len;

    F_LOG_D(logger_, "starting UART channel discovery");

    /* The backend serves one fixed UART (fibre-uart alias); no per-discovery
     * state, so the handle can point at the backend itself. */
    if (handle) {
        *handle = reinterpret_cast<ChannelDiscoveryContext*>(this);
    }

    /* A point-to-point serial link is always connected: report the channel
     * immediately. Raw byte stream, so packetized = false and no MTU limit
     * beyond the protocol's internal buffer sizes. */
    domain->add_legacy_channels({kFibreOk, &stream_, &stream_, SIZE_MAX, false},
                                "UART");
}

RichStatus UartBackend::stop_channel_discovery(ChannelDiscoveryContext* handle) {
    (void)handle;
    /* Nothing to stop: the UART keeps running. */
    return RichStatus::success();
}

/* --------------------------------------------------------------------------
 * RX path
 *
 * ISR: UART FIFO -> ring buffer; posts a completion event if a read is
 * armed. Event loop thread: pops from the ring buffer into the caller's
 * buffer and completes the read (partial reads are allowed, >= 1 byte).
 */

void UartBackend::Stream::start_read(bufptr_t buffer, TransferHandle* handle,
                                     Callback<void, ReadResult> completer) {
    UartBackend* self = parent;

    if (handle) {
        /* Cancel is not supported (never invoked by this app); the handle is
         * still filled in for API conformance. */
        *handle = reinterpret_cast<TransferHandle>(self);
    }

    unsigned key = irq_lock();
    self->rx_active_ = true;
    self->rx_posted_ = false;
    self->rx_buf_ = buffer;
    self->rx_completer_ = completer;
    bool have_data = (self->rx_head_ != self->rx_tail_);
    irq_unlock(key);

    if (have_data) {
        /* Data is already buffered: schedule completion without waiting for
         * the next UART interrupt. rx_posted_ makes this idempotent. */
        key = irq_lock();
        bool need = !self->rx_posted_;
        self->rx_posted_ = true;
        irq_unlock(key);
        if (need) {
            (void)self->event_loop_->post(Callback<void>{self->rx_kick_});
        }
    }
}

void UartBackend::complete_rx() {
    unsigned key = irq_lock();
    rx_posted_ = false;

    size_t n = 0;
    if (rx_active_) {
        uint8_t* dst = rx_buf_.begin();
        size_t max = rx_buf_.size();
        while (n < max && rx_tail_ != rx_head_) {
            dst[n++] = rx_ring_[rx_tail_];
            rx_tail_ = (rx_tail_ + 1) & kRingMask;
        }
    }
    irq_unlock(key);

    if (!rx_active_ || n == 0) {
        return; // spurious wakeup or nothing to deliver yet
    }

    rx_active_ = false;
    rx_completer_.invoke_and_clear(ReadResult{kStreamOk, rx_buf_.begin() + n});
}

/* --------------------------------------------------------------------------
 * TX path
 *
 * The Fibre stack hands over a buffer; the ISR feeds it into the UART FIFO
 * in chunks and posts a completion event once everything was accepted by
 * the hardware.
 */

void UartBackend::Stream::start_write(cbufptr_t buffer, TransferHandle* handle,
                                      Callback<void, WriteResult0> completer) {
    UartBackend* self = parent;

    if (handle) {
        *handle = reinterpret_cast<TransferHandle>(self);
    }

    unsigned key = irq_lock();
    F_LOG_IF(self->logger_, self->tx_active_, "concurrent UART write");
    self->tx_active_ = true;
    self->tx_pos_ = buffer.begin();
    self->tx_end_ = buffer.end();
    self->tx_completer_ = completer;
    irq_unlock(key);

    uart_irq_tx_enable(self->dev_);
}

void UartBackend::finish_tx() {
    /* tx_active_ was already cleared by the ISR before posting. */
    tx_completer_.invoke_and_clear(WriteResult0{kStreamOk, tx_end_});
}

void UartBackend::Stream::cancel_read(TransferHandle transfer_handle) {
    (void)transfer_handle;
    /* Not supported; this app never cancels an in-progress transfer. */
}

void UartBackend::Stream::cancel_write(TransferHandle transfer_handle) {
    (void)transfer_handle;
    /* Not supported; this app never cancels an in-progress transfer. */
}

/* --------------------------------------------------------------------------
 * UART ISR
 */

void UartBackend::uart_isr_(const struct device* dev, void* user_data) {
    UartBackend* self = static_cast<UartBackend*>(user_data);

    while (uart_irq_update(dev) && uart_irq_is_pending(dev)) {
        if (uart_irq_rx_ready(dev)) {
            uint8_t tmp[32];
            int n;
            while ((n = uart_fifo_read(dev, tmp, sizeof(tmp))) > 0) {
                for (int i = 0; i < n; i++) {
                    size_t next = (self->rx_head_ + 1) & kRingMask;
                    if (next == self->rx_tail_) {
                        /* Ring full: drop the byte. The protocol layer
                         * detects the damage via the packet CRC. */
                        self->rx_dropped_++;
                        continue;
                    }
                    self->rx_ring_[self->rx_head_] = tmp[i];
                    self->rx_head_ = next;
                }
            }

            unsigned key = irq_lock();
            bool need = self->rx_active_ && !self->rx_posted_;
            if (need) {
                self->rx_posted_ = true;
            }
            irq_unlock(key);
            if (need) {
                (void)self->event_loop_->post(Callback<void>{self->rx_kick_});
            }
        }

        if (uart_irq_tx_ready(dev)) {
            size_t rem = self->tx_end_ - self->tx_pos_;
            if (rem > 0) {
                int n = uart_fifo_fill(dev, self->tx_pos_, rem);
                if (n > 0) {
                    self->tx_pos_ += n;
                    rem = self->tx_end_ - self->tx_pos_;
                }
            }
            if (rem == 0 && self->tx_active_) {
                uart_irq_tx_disable(dev);
                unsigned key = irq_lock();
                self->tx_active_ = false;
                irq_unlock(key);
                (void)self->event_loop_->post(Callback<void>{self->tx_done_});
            }
        }
    }
}

} // namespace cas_sim
```

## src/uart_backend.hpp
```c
/*
 * SPDX-License-Identifier: Apache-2.0
 *
 * Fibre transport backend over a Zephyr UART (interrupt-driven API),
 * shared with tests/fibre-test (same file, renamed namespace).
 *
 * Bridges the asynchronous stream model of the Fibre stack
 * (AsyncStreamSource / AsyncStreamSink) to the UART ISR:
 *
 *   - The UART ISR only moves bytes between the hardware FIFO and an RX ring
 *     buffer (or the pending TX buffer). It never runs Fibre code.
 *   - Stream completion callbacks are deferred to the Fibre event loop
 *     thread via EventLoop::post(), which is safe from ISR context.
 *
 * The backend serves a single point-to-point channel on the UART selected by
 * the `fibre-uart` devicetree alias. A serial link is always "connected", so
 * the channel is reported as found as soon as a domain starts discovery.
 *
 * Not implemented (not needed by this app, which never tears the transport
 * down): cancel_read() / cancel_write() and repeated
 * start_channel_discovery().
 */

#ifndef CAS_SIM_UART_BACKEND_HPP
#define CAS_SIM_UART_BACKEND_HPP

#include <fibre/bufptr.hpp>
#include <fibre/channel_discoverer.hpp>
#include <fibre/event_loop.hpp>
#include <fibre/logging.hpp>

#include <zephyr/drivers/uart.h>
#include <zephyr/kernel.h>

namespace cas_sim {

class UartBackend final : public fibre::Backend {
public:
    fibre::RichStatus init(fibre::EventLoop* event_loop, fibre::Logger logger) final;
    fibre::RichStatus deinit() final;

    void start_channel_discovery(fibre::Domain* domain, const char* specs,
                                 size_t specs_len,
                                 fibre::ChannelDiscoveryContext** handle) final;
    fibre::RichStatus stop_channel_discovery(fibre::ChannelDiscoveryContext* handle) final;

private:
    /* Ring buffer size (power of two). 512 bytes ≈ 44 ms of buffer at
     * 115200 baud; plenty for the legacy protocol's 128 byte packets. */
    static constexpr size_t kRingSize = 512;
    static constexpr size_t kRingMask = kRingSize - 1;

    /* Persistent functors handed to EventLoop::post(). Callback stores a
     * pointer to the functor, so they must outlive the queued event — hence
     * members, not temporaries. */
    struct RxKick {
        UartBackend* self;
        void operator()() const { self->complete_rx(); }
    };
    struct TxDone {
        UartBackend* self;
        void operator()() const { self->finish_tx(); }
    };

    struct Stream final : fibre::AsyncStreamSource, fibre::AsyncStreamSink {
        UartBackend* parent;

        void start_read(fibre::bufptr_t buffer, fibre::TransferHandle* handle,
                        fibre::Callback<void, fibre::ReadResult> completer) final;
        void cancel_read(fibre::TransferHandle transfer_handle) final;
        void start_write(fibre::cbufptr_t buffer, fibre::TransferHandle* handle,
                         fibre::Callback<void, fibre::WriteResult0> completer) final;
        void cancel_write(fibre::TransferHandle transfer_handle) final;
    };

    /* Event loop thread context */
    void complete_rx();
    void finish_tx();

    friend struct Stream;
    friend struct RxKick;
    friend struct TxDone;

    fibre::EventLoop* event_loop_ = nullptr;
    fibre::Logger logger_ = fibre::Logger::none();
    const struct device* dev_ = nullptr;

    Stream stream_{};
    RxKick rx_kick_{this};
    TxDone tx_done_{this};

    /* RX ring buffer. rx_head_ is advanced by the ISR, rx_tail_ by the event
     * loop thread (under irq_lock()). Both are single-word aligned so access
     * is atomic on ARM. */
    volatile size_t rx_head_ = 0;
    volatile size_t rx_tail_ = 0;
    uint8_t rx_ring_[kRingSize];
    size_t rx_dropped_ = 0;

    /* Pending RX read, armed by the Fibre stack. State changes are guarded
     * with irq_lock() because the ISR also inspects these flags. */
    bool rx_active_ = false;
    bool rx_posted_ = false;
    fibre::bufptr_t rx_buf_{nullptr, nullptr};
    fibre::Callback<void, fibre::ReadResult> rx_completer_;

    /* Pending TX write. One outstanding transfer at a time. */
    bool tx_active_ = false;
    const uint8_t* tx_pos_ = nullptr;
    const uint8_t* tx_end_ = nullptr;
    fibre::Callback<void, fibre::WriteResult0> tx_completer_;

    static void uart_isr_(const struct device* dev, void* user_data);
};

} // namespace cas_sim

#endif // CAS_SIM_UART_BACKEND_HPP
```
